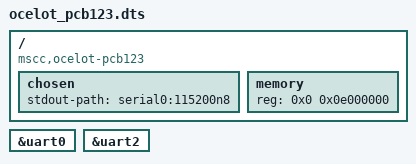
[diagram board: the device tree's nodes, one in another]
/*
 * Copyright (c) 2017 Microsemi Corporation
 *
 * SPDX-License-Identifier: (GPL-2.0 OR MIT)
 */

/dts-v1/;

#include "ocelot.dtsi"

/ {
	compatible = "mscc,ocelot-pcb123", "mscc,ocelot";

	chosen {
		stdout-path = "serial0:115200n8";
	};

	memory {
		device_type = "memory";
		reg = <0x0 0x0e000000>;
	};
};

&uart0 {
	status = "okay";
};

&uart2 {
	status = "okay";
};
